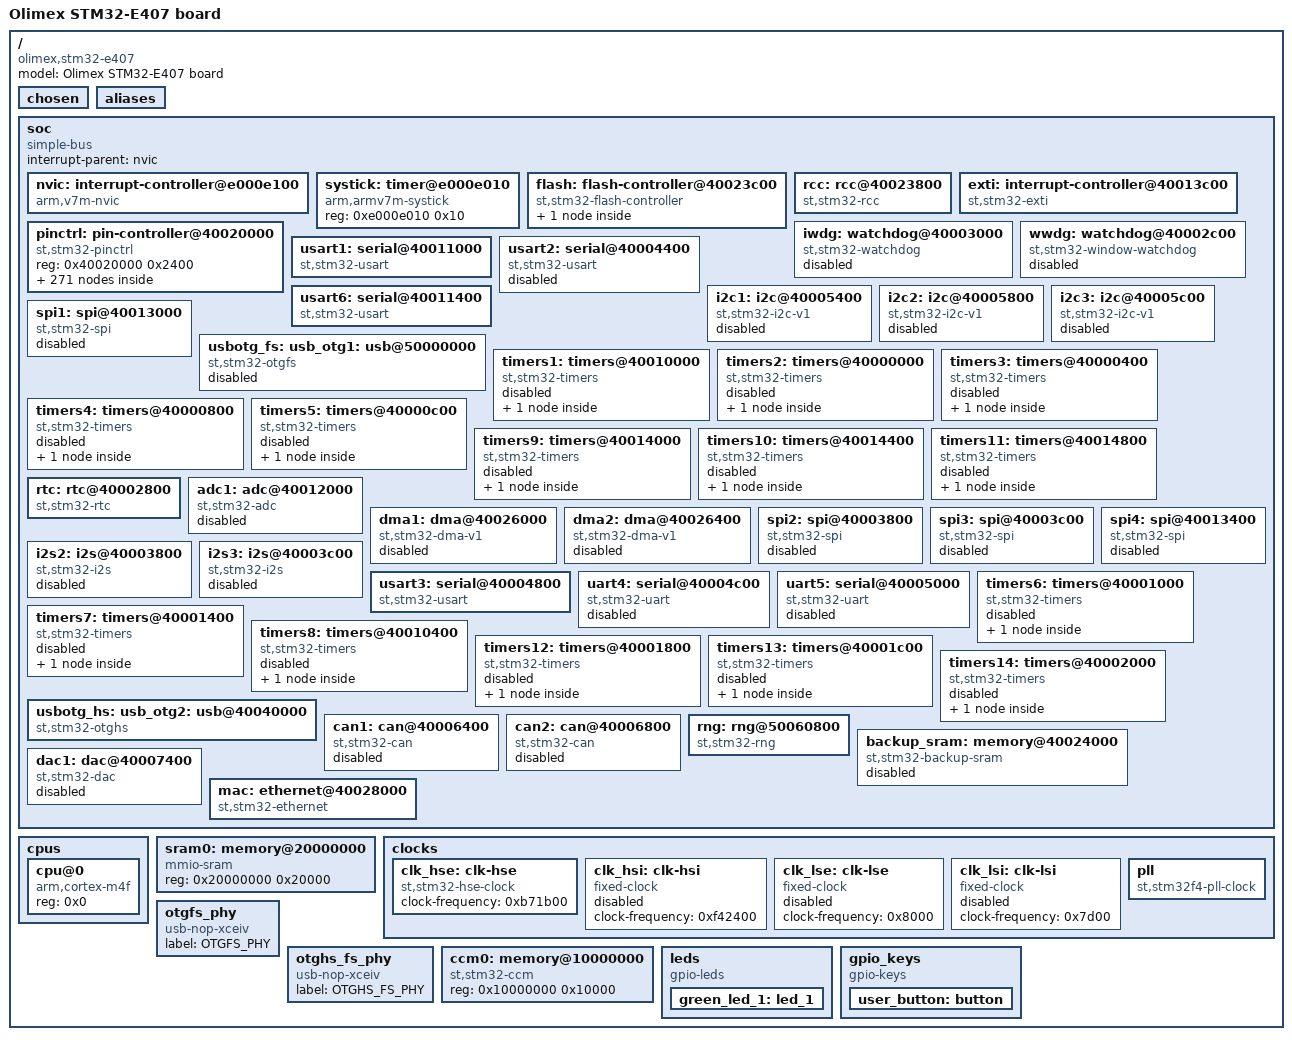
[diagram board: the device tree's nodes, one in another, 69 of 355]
/dts-v1/;

/ {
	#address-cells = < 0x1 >;
	#size-cells = < 0x1 >;
	model = "Olimex STM32-E407 board";
	compatible = "olimex,stm32-e407";
	chosen {
		zephyr,flash-controller = &flash;
		zephyr,entropy = &rng;
		zephyr,console = &usart1;
		zephyr,shell-uart = &usart1;
		zephyr,sram = &sram0;
		zephyr,flash = &flash0;
		zephyr,ccm = &ccm0;
	};
	aliases {
		led0 = &green_led_1;
		sw0 = &user_button;
	};
	soc {
		#address-cells = < 0x1 >;
		#size-cells = < 0x1 >;
		compatible = "simple-bus";
		interrupt-parent = < &nvic >;
		ranges;
		nvic: interrupt-controller@e000e100 {
			compatible = "arm,v7m-nvic";
			reg = < 0xe000e100 0xc00 >;
			interrupt-controller;
			#interrupt-cells = < 0x2 >;
			arm,num-irq-priority-bits = < 0x4 >;
			phandle = < 0x1 >;
		};
		systick: timer@e000e010 {
			compatible = "arm,armv7m-systick";
			reg = < 0xe000e010 0x10 >;
		};
		flash: flash-controller@40023c00 {
			compatible = "st,stm32-flash-controller", "st,stm32f4-flash-controller";
			label = "FLASH_CTRL";
			reg = < 0x40023c00 0x400 >;
			interrupts = < 0x4 0x0 >;
			#address-cells = < 0x1 >;
			#size-cells = < 0x1 >;
			flash0: flash@8000000 {
				compatible = "soc-nv-flash";
				label = "FLASH_STM32";
				write-block-size = < 0x1 >;
				reg = < 0x8000000 0x100000 >;
			};
		};
		rcc: rcc@40023800 {
			compatible = "st,stm32-rcc";
			#clock-cells = < 0x2 >;
			reg = < 0x40023800 0x400 >;
			clocks = < &pll >;
			clock-frequency = < 0xa037a00 >;
			ahb-prescaler = < 0x1 >;
			apb1-prescaler = < 0x4 >;
			apb2-prescaler = < 0x2 >;
			phandle = < 0x3 >;
		};
		exti: interrupt-controller@40013c00 {
			compatible = "st,stm32-exti";
			interrupt-controller;
			#interrupt-cells = < 0x1 >;
			reg = < 0x40013c00 0x400 >;
		};
		pinctrl: pin-controller@40020000 {
			compatible = "st,stm32-pinctrl";
			#address-cells = < 0x1 >;
			#size-cells = < 0x1 >;
			reg = < 0x40020000 0x2400 >;
			gpioa: gpio@40020000 {
				compatible = "st,stm32-gpio";
				gpio-controller;
				#gpio-cells = < 0x2 >;
				reg = < 0x40020000 0x400 >;
				clocks = < &rcc 0x0 0x1 >;
				label = "GPIOA";
				phandle = < 0x1e >;
			};
			gpiob: gpio@40020400 {
				compatible = "st,stm32-gpio";
				gpio-controller;
				#gpio-cells = < 0x2 >;
				reg = < 0x40020400 0x400 >;
				clocks = < &rcc 0x0 0x2 >;
				label = "GPIOB";
				phandle = < 0x8 >;
			};
			gpioc: gpio@40020800 {
				compatible = "st,stm32-gpio";
				gpio-controller;
				#gpio-cells = < 0x2 >;
				reg = < 0x40020800 0x400 >;
				clocks = < &rcc 0x0 0x4 >;
				label = "GPIOC";
				phandle = < 0x1d >;
			};
			gpiod: gpio@40020c00 {
				compatible = "st,stm32-gpio";
				gpio-controller;
				#gpio-cells = < 0x2 >;
				reg = < 0x40020c00 0x400 >;
				clocks = < &rcc 0x0 0x8 >;
				label = "GPIOD";
			};
			gpioe: gpio@40021000 {
				compatible = "st,stm32-gpio";
				gpio-controller;
				#gpio-cells = < 0x2 >;
				reg = < 0x40021000 0x400 >;
				clocks = < &rcc 0x0 0x10 >;
				label = "GPIOE";
			};
			gpioh: gpio@40021c00 {
				compatible = "st,stm32-gpio";
				gpio-controller;
				#gpio-cells = < 0x2 >;
				reg = < 0x40021c00 0x400 >;
				clocks = < &rcc 0x0 0x80 >;
				label = "GPIOH";
			};
			gpiof: gpio@40021400 {
				compatible = "st,stm32-gpio";
				gpio-controller;
				#gpio-cells = < 0x2 >;
				reg = < 0x40021400 0x400 >;
				clocks = < &rcc 0x0 0x20 >;
				label = "GPIOF";
			};
			gpiog: gpio@40021800 {
				compatible = "st,stm32-gpio";
				gpio-controller;
				#gpio-cells = < 0x2 >;
				reg = < 0x40021800 0x400 >;
				clocks = < &rcc 0x0 0x40 >;
				label = "GPIOG";
			};
			gpioi: gpio@40022000 {
				compatible = "st,stm32-gpio";
				gpio-controller;
				#gpio-cells = < 0x2 >;
				reg = < 0x40022000 0x400 >;
				clocks = < &rcc 0x0 0x100 >;
				label = "GPIOI";
			};
			adc1_in0_pa0: adc1_in0_pa0 {
				pinmux = < 0x10 >;
			};
			adc1_in1_pa1: adc1_in1_pa1 {
				pinmux = < 0x110 >;
			};
			adc1_in2_pa2: adc1_in2_pa2 {
				pinmux = < 0x210 >;
			};
			adc1_in3_pa3: adc1_in3_pa3 {
				pinmux = < 0x310 >;
			};
			adc1_in4_pa4: adc1_in4_pa4 {
				pinmux = < 0x410 >;
			};
			adc1_in5_pa5: adc1_in5_pa5 {
				pinmux = < 0x510 >;
			};
			adc1_in6_pa6: adc1_in6_pa6 {
				pinmux = < 0x610 >;
			};
			adc1_in7_pa7: adc1_in7_pa7 {
				pinmux = < 0x710 >;
			};
			adc1_in8_pb0: adc1_in8_pb0 {
				pinmux = < 0x1010 >;
			};
			adc1_in9_pb1: adc1_in9_pb1 {
				pinmux = < 0x1110 >;
			};
			adc1_in10_pc0: adc1_in10_pc0 {
				pinmux = < 0x2010 >;
			};
			adc1_in11_pc1: adc1_in11_pc1 {
				pinmux = < 0x2110 >;
			};
			adc1_in12_pc2: adc1_in12_pc2 {
				pinmux = < 0x2210 >;
			};
			adc1_in13_pc3: adc1_in13_pc3 {
				pinmux = < 0x2310 >;
			};
			adc1_in14_pc4: adc1_in14_pc4 {
				pinmux = < 0x2410 >;
			};
			adc1_in15_pc5: adc1_in15_pc5 {
				pinmux = < 0x2510 >;
			};
			adc2_in0_pa0: adc2_in0_pa0 {
				pinmux = < 0x10 >;
			};
			adc2_in1_pa1: adc2_in1_pa1 {
				pinmux = < 0x110 >;
			};
			adc2_in2_pa2: adc2_in2_pa2 {
				pinmux = < 0x210 >;
			};
			adc2_in3_pa3: adc2_in3_pa3 {
				pinmux = < 0x310 >;
			};
			adc2_in4_pa4: adc2_in4_pa4 {
				pinmux = < 0x410 >;
			};
			adc2_in5_pa5: adc2_in5_pa5 {
				pinmux = < 0x510 >;
			};
			adc2_in6_pa6: adc2_in6_pa6 {
				pinmux = < 0x610 >;
			};
			adc2_in7_pa7: adc2_in7_pa7 {
				pinmux = < 0x710 >;
			};
			adc2_in8_pb0: adc2_in8_pb0 {
				pinmux = < 0x1010 >;
			};
			adc2_in9_pb1: adc2_in9_pb1 {
				pinmux = < 0x1110 >;
			};
			adc2_in10_pc0: adc2_in10_pc0 {
				pinmux = < 0x2010 >;
			};
			adc2_in11_pc1: adc2_in11_pc1 {
				pinmux = < 0x2110 >;
			};
			adc2_in12_pc2: adc2_in12_pc2 {
				pinmux = < 0x2210 >;
			};
			adc2_in13_pc3: adc2_in13_pc3 {
				pinmux = < 0x2310 >;
			};
			adc2_in14_pc4: adc2_in14_pc4 {
				pinmux = < 0x2410 >;
			};
			adc2_in15_pc5: adc2_in15_pc5 {
				pinmux = < 0x2510 >;
			};
			adc3_in0_pa0: adc3_in0_pa0 {
				pinmux = < 0x10 >;
			};
			adc3_in1_pa1: adc3_in1_pa1 {
				pinmux = < 0x110 >;
			};
			adc3_in2_pa2: adc3_in2_pa2 {
				pinmux = < 0x210 >;
			};
			adc3_in3_pa3: adc3_in3_pa3 {
				pinmux = < 0x310 >;
			};
			adc3_in10_pc0: adc3_in10_pc0 {
				pinmux = < 0x2010 >;
			};
			adc3_in11_pc1: adc3_in11_pc1 {
				pinmux = < 0x2110 >;
			};
			adc3_in12_pc2: adc3_in12_pc2 {
				pinmux = < 0x2210 >;
			};
			adc3_in13_pc3: adc3_in13_pc3 {
				pinmux = < 0x2310 >;
			};
			adc3_in9_pf3: adc3_in9_pf3 {
				pinmux = < 0x5310 >;
			};
			adc3_in14_pf4: adc3_in14_pf4 {
				pinmux = < 0x5410 >;
			};
			adc3_in15_pf5: adc3_in15_pf5 {
				pinmux = < 0x5510 >;
			};
			adc3_in4_pf6: adc3_in4_pf6 {
				pinmux = < 0x5610 >;
			};
			adc3_in5_pf7: adc3_in5_pf7 {
				pinmux = < 0x5710 >;
			};
			adc3_in6_pf8: adc3_in6_pf8 {
				pinmux = < 0x5810 >;
			};
			adc3_in7_pf9: adc3_in7_pf9 {
				pinmux = < 0x5910 >;
			};
			adc3_in8_pf10: adc3_in8_pf10 {
				pinmux = < 0x5a10 >;
			};
			can1_rx_pa11: can1_rx_pa11 {
				pinmux = < 0xb09 >;
				bias-pull-up;
			};
			can1_rx_pb8: can1_rx_pb8 {
				pinmux = < 0x1809 >;
				bias-pull-up;
			};
			can1_rx_pd0: can1_rx_pd0 {
				pinmux = < 0x3009 >;
				bias-pull-up;
			};
			can2_rx_pb5: can2_rx_pb5 {
				pinmux = < 0x1509 >;
				bias-pull-up;
			};
			can2_rx_pb12: can2_rx_pb12 {
				pinmux = < 0x1c09 >;
				bias-pull-up;
			};
			can1_tx_pa12: can1_tx_pa12 {
				pinmux = < 0xc09 >;
			};
			can1_tx_pb9: can1_tx_pb9 {
				pinmux = < 0x1909 >;
			};
			can1_tx_pd1: can1_tx_pd1 {
				pinmux = < 0x3109 >;
			};
			can2_tx_pb6: can2_tx_pb6 {
				pinmux = < 0x1609 >;
			};
			can2_tx_pb13: can2_tx_pb13 {
				pinmux = < 0x1d09 >;
			};
			dac_out1_pa4: dac_out1_pa4 {
				pinmux = < 0x410 >;
			};
			dac_out2_pa5: dac_out2_pa5 {
				pinmux = < 0x510 >;
			};
			eth_col_pa3: eth_col_pa3 {
				pinmux = < 0x30b >;
				slew-rate = "very-high-speed";
				phandle = < 0x17 >;
			};
			eth_crs_pa0: eth_crs_pa0 {
				pinmux = < 0xb >;
				slew-rate = "very-high-speed";
			};
			eth_crs_dv_pa7: eth_crs_dv_pa7 {
				pinmux = < 0x70b >;
				slew-rate = "very-high-speed";
				phandle = < 0x18 >;
			};
			eth_mdc_pc1: eth_mdc_pc1 {
				pinmux = < 0x210b >;
				slew-rate = "very-high-speed";
				phandle = < 0x12 >;
			};
			eth_mdio_pa2: eth_mdio_pa2 {
				pinmux = < 0x20b >;
				slew-rate = "very-high-speed";
				phandle = < 0x16 >;
			};
			eth_pps_out_pb5: eth_pps_out_pb5 {
				pinmux = < 0x150b >;
				slew-rate = "very-high-speed";
			};
			eth_pps_out_pg8: eth_pps_out_pg8 {
				pinmux = < 0x680b >;
				slew-rate = "very-high-speed";
			};
			eth_ref_clk_pa1: eth_ref_clk_pa1 {
				pinmux = < 0x10b >;
				slew-rate = "very-high-speed";
				phandle = < 0x15 >;
			};
			eth_rxd0_pc4: eth_rxd0_pc4 {
				pinmux = < 0x240b >;
				slew-rate = "very-high-speed";
				phandle = < 0x13 >;
			};
			eth_rxd1_pc5: eth_rxd1_pc5 {
				pinmux = < 0x250b >;
				slew-rate = "very-high-speed";
				phandle = < 0x14 >;
			};
			eth_rxd2_pb0: eth_rxd2_pb0 {
				pinmux = < 0x100b >;
				slew-rate = "very-high-speed";
			};
			eth_rxd3_pb1: eth_rxd3_pb1 {
				pinmux = < 0x110b >;
				slew-rate = "very-high-speed";
			};
			eth_rx_clk_pa1: eth_rx_clk_pa1 {
				pinmux = < 0x10b >;
				slew-rate = "very-high-speed";
			};
			eth_rx_dv_pa7: eth_rx_dv_pa7 {
				pinmux = < 0x70b >;
				slew-rate = "very-high-speed";
			};
			eth_rx_er_pb10: eth_rx_er_pb10 {
				pinmux = < 0x1a0b >;
				slew-rate = "very-high-speed";
			};
			eth_txd0_pb12: eth_txd0_pb12 {
				pinmux = < 0x1c0b >;
				slew-rate = "very-high-speed";
			};
			eth_txd0_pg13: eth_txd0_pg13 {
				pinmux = < 0x6d0b >;
				slew-rate = "very-high-speed";
				phandle = < 0x1a >;
			};
			eth_txd1_pb13: eth_txd1_pb13 {
				pinmux = < 0x1d0b >;
				slew-rate = "very-high-speed";
			};
			eth_txd1_pg14: eth_txd1_pg14 {
				pinmux = < 0x6e0b >;
				slew-rate = "very-high-speed";
				phandle = < 0x1b >;
			};
			eth_txd2_pc2: eth_txd2_pc2 {
				pinmux = < 0x220b >;
				slew-rate = "very-high-speed";
			};
			eth_txd3_pb8: eth_txd3_pb8 {
				pinmux = < 0x180b >;
				slew-rate = "very-high-speed";
			};
			eth_txd3_pe2: eth_txd3_pe2 {
				pinmux = < 0x420b >;
				slew-rate = "very-high-speed";
			};
			eth_tx_clk_pc3: eth_tx_clk_pc3 {
				pinmux = < 0x230b >;
				slew-rate = "very-high-speed";
			};
			eth_tx_en_pb11: eth_tx_en_pb11 {
				pinmux = < 0x1b0b >;
				slew-rate = "very-high-speed";
			};
			eth_tx_en_pg11: eth_tx_en_pg11 {
				pinmux = < 0x6b0b >;
				slew-rate = "very-high-speed";
				phandle = < 0x19 >;
			};
			i2c1_scl_pb6: i2c1_scl_pb6 {
				pinmux = < 0x1604 >;
				bias-pull-up;
				drive-open-drain;
			};
			i2c1_scl_pb8: i2c1_scl_pb8 {
				pinmux = < 0x1804 >;
				bias-pull-up;
				drive-open-drain;
			};
			i2c2_scl_pb10: i2c2_scl_pb10 {
				pinmux = < 0x1a04 >;
				bias-pull-up;
				drive-open-drain;
			};
			i2c2_scl_pf1: i2c2_scl_pf1 {
				pinmux = < 0x5104 >;
				bias-pull-up;
				drive-open-drain;
			};
			i2c3_scl_pa8: i2c3_scl_pa8 {
				pinmux = < 0x804 >;
				bias-pull-up;
				drive-open-drain;
			};
			i2c1_sda_pb7: i2c1_sda_pb7 {
				pinmux = < 0x1704 >;
				bias-pull-up;
				drive-open-drain;
			};
			i2c1_sda_pb9: i2c1_sda_pb9 {
				pinmux = < 0x1904 >;
				bias-pull-up;
				drive-open-drain;
			};
			i2c2_sda_pb11: i2c2_sda_pb11 {
				pinmux = < 0x1b04 >;
				bias-pull-up;
				drive-open-drain;
			};
			i2c2_sda_pf0: i2c2_sda_pf0 {
				pinmux = < 0x5004 >;
				bias-pull-up;
				drive-open-drain;
			};
			i2c3_sda_pc9: i2c3_sda_pc9 {
				pinmux = < 0x2904 >;
				bias-pull-up;
				drive-open-drain;
			};
			i2s2_ck_pb10: i2s2_ck_pb10 {
				pinmux = < 0x1a05 >;
				slew-rate = "very-high-speed";
			};
			i2s2_ck_pb13: i2s2_ck_pb13 {
				pinmux = < 0x1d05 >;
				slew-rate = "very-high-speed";
			};
			i2s3_ck_pb3: i2s3_ck_pb3 {
				pinmux = < 0x1306 >;
				slew-rate = "very-high-speed";
			};
			i2s3_ck_pc10: i2s3_ck_pc10 {
				pinmux = < 0x2a06 >;
				slew-rate = "very-high-speed";
			};
			i2s2_sd_pb15: i2s2_sd_pb15 {
				pinmux = < 0x1f05 >;
			};
			i2s2_sd_pc3: i2s2_sd_pc3 {
				pinmux = < 0x2305 >;
			};
			i2s3_sd_pb5: i2s3_sd_pb5 {
				pinmux = < 0x1506 >;
			};
			i2s3_sd_pc12: i2s3_sd_pc12 {
				pinmux = < 0x2c06 >;
			};
			i2s2_ws_pb9: i2s2_ws_pb9 {
				pinmux = < 0x1905 >;
			};
			i2s2_ws_pb12: i2s2_ws_pb12 {
				pinmux = < 0x1c05 >;
			};
			i2s3_ws_pa4: i2s3_ws_pa4 {
				pinmux = < 0x406 >;
			};
			i2s3_ws_pa15: i2s3_ws_pa15 {
				pinmux = < 0xf06 >;
			};
			spi1_miso_pa6: spi1_miso_pa6 {
				pinmux = < 0x605 >;
				bias-pull-down;
			};
			spi1_miso_pb4: spi1_miso_pb4 {
				pinmux = < 0x1405 >;
				bias-pull-down;
			};
			spi2_miso_pb14: spi2_miso_pb14 {
				pinmux = < 0x1e05 >;
				bias-pull-down;
			};
			spi2_miso_pc2: spi2_miso_pc2 {
				pinmux = < 0x2205 >;
				bias-pull-down;
			};
			spi3_miso_pb4: spi3_miso_pb4 {
				pinmux = < 0x1406 >;
				bias-pull-down;
			};
			spi3_miso_pc11: spi3_miso_pc11 {
				pinmux = < 0x2b06 >;
				bias-pull-down;
			};
			spi1_mosi_pa7: spi1_mosi_pa7 {
				pinmux = < 0x705 >;
				bias-pull-down;
			};
			spi1_mosi_pb5: spi1_mosi_pb5 {
				pinmux = < 0x1505 >;
				bias-pull-down;
			};
			spi2_mosi_pb15: spi2_mosi_pb15 {
				pinmux = < 0x1f05 >;
				bias-pull-down;
			};
			spi2_mosi_pc3: spi2_mosi_pc3 {
				pinmux = < 0x2305 >;
				bias-pull-down;
			};
			spi3_mosi_pb5: spi3_mosi_pb5 {
				pinmux = < 0x1506 >;
				bias-pull-down;
			};
			spi3_mosi_pc12: spi3_mosi_pc12 {
				pinmux = < 0x2c06 >;
				bias-pull-down;
			};
			spi1_nss_pa4: spi1_nss_pa4 {
				pinmux = < 0x405 >;
				bias-pull-up;
			};
			spi1_nss_pa15: spi1_nss_pa15 {
				pinmux = < 0xf05 >;
				bias-pull-up;
			};
			spi2_nss_pb9: spi2_nss_pb9 {
				pinmux = < 0x1905 >;
				bias-pull-up;
			};
			spi2_nss_pb12: spi2_nss_pb12 {
				pinmux = < 0x1c05 >;
				bias-pull-up;
			};
			spi3_nss_pa4: spi3_nss_pa4 {
				pinmux = < 0x406 >;
				bias-pull-up;
			};
			spi3_nss_pa15: spi3_nss_pa15 {
				pinmux = < 0xf06 >;
				bias-pull-up;
			};
			spi1_sck_pa5: spi1_sck_pa5 {
				pinmux = < 0x505 >;
				bias-pull-down;
				slew-rate = "very-high-speed";
			};
			spi1_sck_pb3: spi1_sck_pb3 {
				pinmux = < 0x1305 >;
				bias-pull-down;
				slew-rate = "very-high-speed";
			};
			spi2_sck_pb10: spi2_sck_pb10 {
				pinmux = < 0x1a05 >;
				bias-pull-down;
				slew-rate = "very-high-speed";
			};
			spi2_sck_pb13: spi2_sck_pb13 {
				pinmux = < 0x1d05 >;
				bias-pull-down;
				slew-rate = "very-high-speed";
			};
			spi3_sck_pb3: spi3_sck_pb3 {
				pinmux = < 0x1306 >;
				bias-pull-down;
				slew-rate = "very-high-speed";
			};
			spi3_sck_pc10: spi3_sck_pc10 {
				pinmux = < 0x2a06 >;
				bias-pull-down;
				slew-rate = "very-high-speed";
			};
			tim10_ch1_pb8: tim10_ch1_pb8 {
				pinmux = < 0x1803 >;
			};
			tim10_ch1_pf6: tim10_ch1_pf6 {
				pinmux = < 0x5603 >;
			};
			tim1_ch1n_pa7: tim1_ch1n_pa7 {
				pinmux = < 0x701 >;
			};
			tim1_ch1_pa8: tim1_ch1_pa8 {
				pinmux = < 0x801 >;
			};
			tim1_ch2_pa9: tim1_ch2_pa9 {
				pinmux = < 0x901 >;
			};
			tim1_ch3_pa10: tim1_ch3_pa10 {
				pinmux = < 0xa01 >;
			};
			tim1_ch4_pa11: tim1_ch4_pa11 {
				pinmux = < 0xb01 >;
			};
			tim1_ch2n_pb0: tim1_ch2n_pb0 {
				pinmux = < 0x1001 >;
			};
			tim1_ch3n_pb1: tim1_ch3n_pb1 {
				pinmux = < 0x1101 >;
			};
			tim11_ch1_pb9: tim11_ch1_pb9 {
				pinmux = < 0x1903 >;
			};
			tim1_ch1n_pb13: tim1_ch1n_pb13 {
				pinmux = < 0x1d01 >;
			};
			tim1_ch2n_pb14: tim1_ch2n_pb14 {
				pinmux = < 0x1e01 >;
			};
			tim1_ch3n_pb15: tim1_ch3n_pb15 {
				pinmux = < 0x1f01 >;
			};
			tim1_ch1n_pe8: tim1_ch1n_pe8 {
				pinmux = < 0x4801 >;
			};
			tim1_ch1_pe9: tim1_ch1_pe9 {
				pinmux = < 0x4901 >;
			};
			tim1_ch2n_pe10: tim1_ch2n_pe10 {
				pinmux = < 0x4a01 >;
			};
			tim1_ch2_pe11: tim1_ch2_pe11 {
				pinmux = < 0x4b01 >;
			};
			tim1_ch3n_pe12: tim1_ch3n_pe12 {
				pinmux = < 0x4c01 >;
			};
			tim1_ch3_pe13: tim1_ch3_pe13 {
				pinmux = < 0x4d01 >;
			};
			tim1_ch4_pe14: tim1_ch4_pe14 {
				pinmux = < 0x4e01 >;
			};
			tim11_ch1_pf7: tim11_ch1_pf7 {
				pinmux = < 0x5703 >;
			};
			tim2_ch1_pa0: tim2_ch1_pa0 {
				pinmux = < 0x1 >;
			};
			tim2_ch2_pa1: tim2_ch2_pa1 {
				pinmux = < 0x101 >;
			};
			tim2_ch3_pa2: tim2_ch3_pa2 {
				pinmux = < 0x201 >;
			};
			tim2_ch4_pa3: tim2_ch4_pa3 {
				pinmux = < 0x301 >;
			};
			tim2_ch1_pa5: tim2_ch1_pa5 {
				pinmux = < 0x501 >;
			};
			tim2_ch1_pa15: tim2_ch1_pa15 {
				pinmux = < 0xf01 >;
			};
			tim2_ch2_pb3: tim2_ch2_pb3 {
				pinmux = < 0x1301 >;
			};
			tim2_ch3_pb10: tim2_ch3_pb10 {
				pinmux = < 0x1a01 >;
			};
			tim2_ch4_pb11: tim2_ch4_pb11 {
				pinmux = < 0x1b01 >;
			};
			tim12_ch1_pb14: tim12_ch1_pb14 {
				pinmux = < 0x1e09 >;
			};
			tim12_ch2_pb15: tim12_ch2_pb15 {
				pinmux = < 0x1f09 >;
			};
			tim13_ch1_pa6: tim13_ch1_pa6 {
				pinmux = < 0x609 >;
			};
			tim3_ch1_pa6: tim3_ch1_pa6 {
				pinmux = < 0x602 >;
			};
			tim3_ch2_pa7: tim3_ch2_pa7 {
				pinmux = < 0x702 >;
			};
			tim3_ch3_pb0: tim3_ch3_pb0 {
				pinmux = < 0x1002 >;
			};
			tim3_ch4_pb1: tim3_ch4_pb1 {
				pinmux = < 0x1102 >;
			};
			tim3_ch1_pb4: tim3_ch1_pb4 {
				pinmux = < 0x1402 >;
			};
			tim3_ch2_pb5: tim3_ch2_pb5 {
				pinmux = < 0x1502 >;
			};
			tim3_ch1_pc6: tim3_ch1_pc6 {
				pinmux = < 0x2602 >;
			};
			tim3_ch2_pc7: tim3_ch2_pc7 {
				pinmux = < 0x2702 >;
			};
			tim3_ch3_pc8: tim3_ch3_pc8 {
				pinmux = < 0x2802 >;
			};
			tim3_ch4_pc9: tim3_ch4_pc9 {
				pinmux = < 0x2902 >;
			};
			tim13_ch1_pf8: tim13_ch1_pf8 {
				pinmux = < 0x5809 >;
			};
			tim14_ch1_pa7: tim14_ch1_pa7 {
				pinmux = < 0x709 >;
			};
			tim4_ch1_pb6: tim4_ch1_pb6 {
				pinmux = < 0x1602 >;
			};
			tim4_ch2_pb7: tim4_ch2_pb7 {
				pinmux = < 0x1702 >;
			};
			tim4_ch3_pb8: tim4_ch3_pb8 {
				pinmux = < 0x1802 >;
			};
			tim4_ch4_pb9: tim4_ch4_pb9 {
				pinmux = < 0x1902 >;
			};
			tim4_ch1_pd12: tim4_ch1_pd12 {
				pinmux = < 0x3c02 >;
			};
			tim4_ch2_pd13: tim4_ch2_pd13 {
				pinmux = < 0x3d02 >;
			};
			tim4_ch3_pd14: tim4_ch3_pd14 {
				pinmux = < 0x3e02 >;
			};
			tim4_ch4_pd15: tim4_ch4_pd15 {
				pinmux = < 0x3f02 >;
			};
			tim14_ch1_pf9: tim14_ch1_pf9 {
				pinmux = < 0x5909 >;
			};
			tim5_ch1_pa0: tim5_ch1_pa0 {
				pinmux = < 0x2 >;
			};
			tim5_ch2_pa1: tim5_ch2_pa1 {
				pinmux = < 0x102 >;
			};
			tim5_ch3_pa2: tim5_ch3_pa2 {
				pinmux = < 0x202 >;
			};
			tim5_ch4_pa3: tim5_ch4_pa3 {
				pinmux = < 0x302 >;
			};
			tim8_ch1n_pa5: tim8_ch1n_pa5 {
				pinmux = < 0x503 >;
			};
			tim8_ch1n_pa7: tim8_ch1n_pa7 {
				pinmux = < 0x703 >;
			};
			tim8_ch2n_pb0: tim8_ch2n_pb0 {
				pinmux = < 0x1003 >;
			};
			tim8_ch3n_pb1: tim8_ch3n_pb1 {
				pinmux = < 0x1103 >;
			};
			tim8_ch2n_pb14: tim8_ch2n_pb14 {
				pinmux = < 0x1e03 >;
			};
			tim8_ch3n_pb15: tim8_ch3n_pb15 {
				pinmux = < 0x1f03 >;
			};
			tim8_ch1_pc6: tim8_ch1_pc6 {
				pinmux = < 0x2603 >;
			};
			tim8_ch2_pc7: tim8_ch2_pc7 {
				pinmux = < 0x2703 >;
			};
			tim8_ch3_pc8: tim8_ch3_pc8 {
				pinmux = < 0x2803 >;
			};
			tim8_ch4_pc9: tim8_ch4_pc9 {
				pinmux = < 0x2903 >;
			};
			tim9_ch1_pa2: tim9_ch1_pa2 {
				pinmux = < 0x203 >;
			};
			tim9_ch2_pa3: tim9_ch2_pa3 {
				pinmux = < 0x303 >;
			};
			tim9_ch1_pe5: tim9_ch1_pe5 {
				pinmux = < 0x4503 >;
			};
			tim9_ch2_pe6: tim9_ch2_pe6 {
				pinmux = < 0x4603 >;
			};
			usart1_cts_pa11: usart1_cts_pa11 {
				pinmux = < 0xb07 >;
				bias-pull-up;
				drive-open-drain;
			};
			usart2_cts_pa0: usart2_cts_pa0 {
				pinmux = < 0x7 >;
				bias-pull-up;
				drive-open-drain;
			};
			usart2_cts_pd3: usart2_cts_pd3 {
				pinmux = < 0x3307 >;
				bias-pull-up;
				drive-open-drain;
			};
			usart3_cts_pb13: usart3_cts_pb13 {
				pinmux = < 0x1d07 >;
				bias-pull-up;
				drive-open-drain;
			};
			usart3_cts_pd11: usart3_cts_pd11 {
				pinmux = < 0x3b07 >;
				bias-pull-up;
				drive-open-drain;
			};
			usart6_cts_pg13: usart6_cts_pg13 {
				pinmux = < 0x6d08 >;
				bias-pull-up;
				drive-open-drain;
			};
			usart6_cts_pg15: usart6_cts_pg15 {
				pinmux = < 0x6f08 >;
				bias-pull-up;
				drive-open-drain;
			};
			usart1_rts_pa12: usart1_rts_pa12 {
				pinmux = < 0xc07 >;
				bias-pull-up;
				drive-open-drain;
			};
			usart2_rts_pa1: usart2_rts_pa1 {
				pinmux = < 0x107 >;
				bias-pull-up;
				drive-open-drain;
			};
			usart2_rts_pd4: usart2_rts_pd4 {
				pinmux = < 0x3407 >;
				bias-pull-up;
				drive-open-drain;
			};
			usart3_rts_pb14: usart3_rts_pb14 {
				pinmux = < 0x1e07 >;
				bias-pull-up;
				drive-open-drain;
			};
			usart3_rts_pd12: usart3_rts_pd12 {
				pinmux = < 0x3c07 >;
				bias-pull-up;
				drive-open-drain;
			};
			usart6_rts_pg8: usart6_rts_pg8 {
				pinmux = < 0x6808 >;
				bias-pull-up;
				drive-open-drain;
			};
			usart6_rts_pg12: usart6_rts_pg12 {
				pinmux = < 0x6c08 >;
				bias-pull-up;
				drive-open-drain;
			};
			usart1_rx_pa10: usart1_rx_pa10 {
				pinmux = < 0xa07 >;
			};
			usart1_rx_pb7: usart1_rx_pb7 {
				pinmux = < 0x1707 >;
				phandle = < 0x5 >;
			};
			usart2_rx_pa3: usart2_rx_pa3 {
				pinmux = < 0x307 >;
			};
			usart2_rx_pd6: usart2_rx_pd6 {
				pinmux = < 0x3607 >;
			};
			usart3_rx_pb11: usart3_rx_pb11 {
				pinmux = < 0x1b07 >;
				phandle = < 0xe >;
			};
			usart3_rx_pc11: usart3_rx_pc11 {
				pinmux = < 0x2b07 >;
			};
			usart3_rx_pd9: usart3_rx_pd9 {
				pinmux = < 0x3907 >;
			};
			uart4_rx_pa1: uart4_rx_pa1 {
				pinmux = < 0x108 >;
			};
			uart4_rx_pc11: uart4_rx_pc11 {
				pinmux = < 0x2b08 >;
			};
			uart5_rx_pd2: uart5_rx_pd2 {
				pinmux = < 0x3208 >;
			};
			usart6_rx_pc7: usart6_rx_pc7 {
				pinmux = < 0x2708 >;
				phandle = < 0x7 >;
			};
			usart6_rx_pg9: usart6_rx_pg9 {
				pinmux = < 0x6908 >;
			};
			usart1_tx_pa9: usart1_tx_pa9 {
				pinmux = < 0x907 >;
				bias-pull-up;
			};
			usart1_tx_pb6: usart1_tx_pb6 {
				pinmux = < 0x1607 >;
				bias-pull-up;
				phandle = < 0x4 >;
			};
			usart2_tx_pa2: usart2_tx_pa2 {
				pinmux = < 0x207 >;
				bias-pull-up;
			};
			usart2_tx_pd5: usart2_tx_pd5 {
				pinmux = < 0x3507 >;
				bias-pull-up;
			};
			usart3_tx_pb10: usart3_tx_pb10 {
				pinmux = < 0x1a07 >;
				bias-pull-up;
				phandle = < 0xd >;
			};
			usart3_tx_pc10: usart3_tx_pc10 {
				pinmux = < 0x2a07 >;
				bias-pull-up;
			};
			usart3_tx_pd8: usart3_tx_pd8 {
				pinmux = < 0x3807 >;
				bias-pull-up;
			};
			uart4_tx_pa0: uart4_tx_pa0 {
				pinmux = < 0x8 >;
				bias-pull-up;
			};
			uart4_tx_pc10: uart4_tx_pc10 {
				pinmux = < 0x2a08 >;
				bias-pull-up;
			};
			uart5_tx_pc12: uart5_tx_pc12 {
				pinmux = < 0x2c08 >;
				bias-pull-up;
			};
			usart6_tx_pc6: usart6_tx_pc6 {
				pinmux = < 0x2608 >;
				bias-pull-up;
				phandle = < 0x6 >;
			};
			usart6_tx_pg14: usart6_tx_pg14 {
				pinmux = < 0x6e08 >;
				bias-pull-up;
			};
			usb_otg_fs_sof_pa8: usb_otg_fs_sof_pa8 {
				pinmux = < 0x80a >;
			};
			usb_otg_fs_vbus_pa9: usb_otg_fs_vbus_pa9 {
				pinmux = < 0x910 >;
			};
			usb_otg_fs_id_pa10: usb_otg_fs_id_pa10 {
				pinmux = < 0xa0a >;
			};
			usb_otg_fs_dm_pa11: usb_otg_fs_dm_pa11 {
				pinmux = < 0xb0a >;
				phandle = < 0xa >;
			};
			usb_otg_fs_dp_pa12: usb_otg_fs_dp_pa12 {
				pinmux = < 0xc0a >;
				phandle = < 0xb >;
			};
			usb_otg_hs_sof_pa4: usb_otg_hs_sof_pa4 {
				pinmux = < 0x40c >;
			};
			usb_otg_hs_id_pb12: usb_otg_hs_id_pb12 {
				pinmux = < 0x1c0c >;
			};
			usb_otg_hs_vbus_pb13: usb_otg_hs_vbus_pb13 {
				pinmux = < 0x1d10 >;
			};
			usb_otg_hs_dm_pb14: usb_otg_hs_dm_pb14 {
				pinmux = < 0x1e0c >;
				phandle = < 0x10 >;
			};
			usb_otg_hs_dp_pb15: usb_otg_hs_dp_pb15 {
				pinmux = < 0x1f0c >;
				phandle = < 0x11 >;
			};
			usb_otg_hs_ulpi_d0_pa3: usb_otg_hs_ulpi_d0_pa3 {
				pinmux = < 0x30a >;
			};
			usb_otg_hs_ulpi_d1_pb0: usb_otg_hs_ulpi_d1_pb0 {
				pinmux = < 0x100a >;
			};
			usb_otg_hs_ulpi_d2_pb1: usb_otg_hs_ulpi_d2_pb1 {
				pinmux = < 0x110a >;
			};
			usb_otg_hs_ulpi_d7_pb5: usb_otg_hs_ulpi_d7_pb5 {
				pinmux = < 0x150a >;
			};
			usb_otg_hs_ulpi_d3_pb10: usb_otg_hs_ulpi_d3_pb10 {
				pinmux = < 0x1a0a >;
			};
			usb_otg_hs_ulpi_d4_pb11: usb_otg_hs_ulpi_d4_pb11 {
				pinmux = < 0x1b0a >;
			};
			usb_otg_hs_ulpi_d5_pb12: usb_otg_hs_ulpi_d5_pb12 {
				pinmux = < 0x1c0a >;
			};
			usb_otg_hs_ulpi_d6_pb13: usb_otg_hs_ulpi_d6_pb13 {
				pinmux = < 0x1d0a >;
			};
			usb_otg_hs_ulpi_stp_pc0: usb_otg_hs_ulpi_stp_pc0 {
				pinmux = < 0x200a >;
			};
			usb_otg_hs_ulpi_dir_pc2: usb_otg_hs_ulpi_dir_pc2 {
				pinmux = < 0x220a >;
			};
			usb_otg_hs_ulpi_nxt_pc3: usb_otg_hs_ulpi_nxt_pc3 {
				pinmux = < 0x230a >;
			};
		};
		iwdg: watchdog@40003000 {
			compatible = "st,stm32-watchdog";
			reg = < 0x40003000 0x400 >;
			label = "IWDG";
			status = "disabled";
		};
		wwdg: watchdog@40002c00 {
			compatible = "st,stm32-window-watchdog";
			reg = < 0x40002c00 0x400 >;
			clocks = < &rcc 0x2 0x800 >;
			label = "WWDG";
			interrupts = < 0x0 0x7 >;
			status = "disabled";
		};
		usart1: serial@40011000 {
			compatible = "st,stm32-usart", "st,stm32-uart";
			reg = < 0x40011000 0x400 >;
			clocks = < &rcc 0x3 0x10 >;
			interrupts = < 0x25 0x0 >;
			status = "okay";
			label = "UART_1";
			pinctrl-0 = < &usart1_tx_pb6 &usart1_rx_pb7 >;
			current-speed = < 0x1c200 >;
		};
		usart2: serial@40004400 {
			compatible = "st,stm32-usart", "st,stm32-uart";
			reg = < 0x40004400 0x400 >;
			clocks = < &rcc 0x2 0x20000 >;
			interrupts = < 0x26 0x0 >;
			status = "disabled";
			label = "UART_2";
		};
		usart6: serial@40011400 {
			compatible = "st,stm32-usart", "st,stm32-uart";
			reg = < 0x40011400 0x400 >;
			clocks = < &rcc 0x3 0x20 >;
			interrupts = < 0x47 0x0 >;
			status = "okay";
			label = "UART_6";
			pinctrl-0 = < &usart6_tx_pc6 &usart6_rx_pc7 >;
			current-speed = < 0x1c200 >;
		};
		i2c1: i2c@40005400 {
			compatible = "st,stm32-i2c-v1";
			clock-frequency = < 0x186a0 >;
			#address-cells = < 0x1 >;
			#size-cells = < 0x0 >;
			reg = < 0x40005400 0x400 >;
			clocks = < &rcc 0x2 0x200000 >;
			interrupts = < 0x1f 0x0 >, < 0x20 0x0 >;
			interrupt-names = "event", "error";
			status = "disabled";
			label = "I2C_1";
		};
		i2c2: i2c@40005800 {
			compatible = "st,stm32-i2c-v1";
			clock-frequency = < 0x186a0 >;
			#address-cells = < 0x1 >;
			#size-cells = < 0x0 >;
			reg = < 0x40005800 0x400 >;
			clocks = < &rcc 0x2 0x400000 >;
			interrupts = < 0x21 0x0 >, < 0x22 0x0 >;
			interrupt-names = "event", "error";
			status = "disabled";
			label = "I2C_2";
		};
		i2c3: i2c@40005c00 {
			compatible = "st,stm32-i2c-v1";
			clock-frequency = < 0x186a0 >;
			#address-cells = < 0x1 >;
			#size-cells = < 0x0 >;
			reg = < 0x40005c00 0x400 >;
			clocks = < &rcc 0x2 0x800000 >;
			interrupts = < 0x48 0x0 >, < 0x49 0x0 >;
			interrupt-names = "event", "error";
			status = "disabled";
			label = "I2C_3";
		};
		spi1: spi@40013000 {
			compatible = "st,stm32-spi";
			#address-cells = < 0x1 >;
			#size-cells = < 0x0 >;
			reg = < 0x40013000 0x400 >;
			clocks = < &rcc 0x3 0x1000 >;
			interrupts = < 0x23 0x5 >;
			status = "disabled";
			label = "SPI_1";
			cs-gpios = < &gpiob 0x6 0x1 >;
		};
		usbotg_fs: usb_otg1: usb@50000000 {
			compatible = "st,stm32-otgfs";
			reg = < 0x50000000 0x40000 >;
			interrupts = < 0x43 0x0 >;
			interrupt-names = "otgfs";
			num-bidir-endpoints = < 0x4 >;
			ram-size = < 0x500 >;
			maximum-speed = "full-speed";
			phys = < &otgfs_phy >;
			clocks = < &rcc 0x1 0x80 >;
			status = "disabled";
			label = "OTGFS";
			pinctrl-0 = < &usb_otg_fs_dm_pa11 &usb_otg_fs_dp_pa12 >;
		};
		timers1: timers@40010000 {
			compatible = "st,stm32-timers";
			reg = < 0x40010000 0x400 >;
			clocks = < &rcc 0x3 0x1 >;
			interrupts = < 0x18 0x0 >, < 0x19 0x0 >, < 0x1a 0x0 >, < 0x1b 0x0 >;
			interrupt-names = "brk", "up", "trgcom", "cc";
			status = "disabled";
			label = "TIMERS_1";
			pwm {
				compatible = "st,stm32-pwm";
				status = "disabled";
				st,prescaler = < 0x2710 >;
				label = "PWM_1";
				#pwm-cells = < 0x3 >;
			};
		};
		timers2: timers@40000000 {
			compatible = "st,stm32-timers";
			reg = < 0x40000000 0x400 >;
			clocks = < &rcc 0x2 0x1 >;
			interrupts = < 0x1c 0x0 >;
			interrupt-names = "global";
			status = "disabled";
			label = "TIMERS_2";
			pwm {
				compatible = "st,stm32-pwm";
				status = "disabled";
				st,prescaler = < 0x0 >;
				label = "PWM_2";
				#pwm-cells = < 0x3 >;
			};
		};
		timers3: timers@40000400 {
			compatible = "st,stm32-timers";
			reg = < 0x40000400 0x400 >;
			clocks = < &rcc 0x2 0x2 >;
			interrupts = < 0x1d 0x0 >;
			interrupt-names = "global";
			status = "disabled";
			label = "TIMERS_3";
			pwm {
				compatible = "st,stm32-pwm";
				status = "disabled";
				st,prescaler = < 0x2710 >;
				label = "PWM_3";
				#pwm-cells = < 0x3 >;
			};
		};
		timers4: timers@40000800 {
			compatible = "st,stm32-timers";
			reg = < 0x40000800 0x400 >;
			clocks = < &rcc 0x2 0x4 >;
			interrupts = < 0x1e 0x0 >;
			interrupt-names = "global";
			status = "disabled";
			label = "TIMERS_4";
			pwm {
				compatible = "st,stm32-pwm";
				status = "disabled";
				st,prescaler = < 0x2710 >;
				label = "PWM_4";
				#pwm-cells = < 0x3 >;
			};
		};
		timers5: timers@40000c00 {
			compatible = "st,stm32-timers";
			reg = < 0x40000c00 0x400 >;
			clocks = < &rcc 0x2 0x8 >;
			interrupts = < 0x32 0x0 >;
			interrupt-names = "global";
			status = "disabled";
			label = "TIMERS_5";
			pwm {
				compatible = "st,stm32-pwm";
				status = "disabled";
				st,prescaler = < 0x0 >;
				label = "PWM_5";
				#pwm-cells = < 0x3 >;
			};
		};
		timers9: timers@40014000 {
			compatible = "st,stm32-timers";
			reg = < 0x40014000 0x400 >;
			clocks = < &rcc 0x3 0x10000 >;
			interrupts = < 0x18 0x0 >;
			interrupt-names = "global";
			status = "disabled";
			label = "TIMERS_9";
			pwm {
				compatible = "st,stm32-pwm";
				status = "disabled";
				st,prescaler = < 0x2710 >;
				label = "PWM_9";
				#pwm-cells = < 0x3 >;
			};
		};
		timers10: timers@40014400 {
			compatible = "st,stm32-timers";
			reg = < 0x40014400 0x400 >;
			clocks = < &rcc 0x3 0x20000 >;
			interrupts = < 0x19 0x0 >;
			interrupt-names = "global";
			status = "disabled";
			label = "TIMERS_10";
			pwm {
				compatible = "st,stm32-pwm";
				status = "disabled";
				st,prescaler = < 0x2710 >;
				label = "PWM_10";
				#pwm-cells = < 0x3 >;
			};
		};
		timers11: timers@40014800 {
			compatible = "st,stm32-timers";
			reg = < 0x40014800 0x400 >;
			clocks = < &rcc 0x3 0x40000 >;
			interrupts = < 0x1a 0x0 >;
			interrupt-names = "global";
			status = "disabled";
			label = "TIMERS_11";
			pwm {
				compatible = "st,stm32-pwm";
				status = "disabled";
				st,prescaler = < 0x2710 >;
				label = "PWM_11";
				#pwm-cells = < 0x3 >;
			};
		};
		rtc: rtc@40002800 {
			compatible = "st,stm32-rtc";
			reg = < 0x40002800 0x400 >;
			interrupts = < 0x29 0x0 >;
			clocks = < &rcc 0x2 0x10000000 >;
			prescaler = < 0x8000 >;
			status = "okay";
			label = "RTC_0";
		};
		adc1: adc@40012000 {
			compatible = "st,stm32-adc";
			reg = < 0x40012000 0x400 >;
			clocks = < &rcc 0x3 0x100 >;
			interrupts = < 0x12 0x0 >;
			status = "disabled";
			label = "ADC_1";
			#io-channel-cells = < 0x1 >;
		};
		dma1: dma@40026000 {
			compatible = "st,stm32-dma-v1";
			#dma-cells = < 0x4 >;
			reg = < 0x40026000 0x400 >;
			interrupts = < 0xb 0x0 0xc 0x0 0xd 0x0 0xe 0x0 0xf 0x0 0x10 0x0 0x11 0x0 0x2f 0x0 >;
			clocks = < &rcc 0x0 0x200000 >;
			status = "disabled";
			label = "DMA_1";
			phandle = < 0xc >;
		};
		dma2: dma@40026400 {
			compatible = "st,stm32-dma-v1";
			#dma-cells = < 0x4 >;
			reg = < 0x40026400 0x400 >;
			interrupts = < 0x38 0x0 0x39 0x0 0x3a 0x0 0x3b 0x0 0x3c 0x0 0x44 0x0 0x45 0x0 0x46 0x0 >;
			clocks = < &rcc 0x0 0x400000 >;
			st,mem2mem;
			status = "disabled";
			label = "DMA_2";
		};
		spi2: spi@40003800 {
			compatible = "st,stm32-spi";
			#address-cells = < 0x1 >;
			#size-cells = < 0x0 >;
			reg = < 0x40003800 0x400 >;
			clocks = < &rcc 0x2 0x4000 >;
			interrupts = < 0x24 0x5 >;
			status = "disabled";
			label = "SPI_2";
		};
		spi3: spi@40003c00 {
			compatible = "st,stm32-spi";
			#address-cells = < 0x1 >;
			#size-cells = < 0x0 >;
			reg = < 0x40003c00 0x400 >;
			clocks = < &rcc 0x2 0x8000 >;
			interrupts = < 0x33 0x5 >;
			status = "disabled";
			label = "SPI_3";
		};
		spi4: spi@40013400 {
			compatible = "st,stm32-spi";
			#address-cells = < 0x1 >;
			#size-cells = < 0x0 >;
			reg = < 0x40013400 0x400 >;
			clocks = < &rcc 0x3 0x2000 >;
			interrupts = < 0x54 0x5 >;
			status = "disabled";
			label = "SPI_4";
		};
		i2s2: i2s@40003800 {
			compatible = "st,stm32-i2s";
			#address-cells = < 0x1 >;
			#size-cells = < 0x0 >;
			reg = < 0x40003800 0x400 >;
			clocks = < &rcc 0x2 0x4000 >;
			interrupts = < 0x24 0x5 >;
			dmas = < &dma1 0x4 0x0 0x400 0x3 &dma1 0x3 0x0 0x400 0x3 >;
			dma-names = "tx", "rx";
			status = "disabled";
			label = "I2S_2";
		};
		i2s3: i2s@40003c00 {
			compatible = "st,stm32-i2s";
			#address-cells = < 0x1 >;
			#size-cells = < 0x0 >;
			reg = < 0x40003c00 0x400 >;
			clocks = < &rcc 0x2 0x8000 >;
			interrupts = < 0x33 0x5 >;
			dmas = < &dma1 0x5 0x0 0x400 0x3 &dma1 0x0 0x0 0x400 0x3 >;
			dma-names = "tx", "rx";
			status = "disabled";
			label = "I2S_3";
		};
		usart3: serial@40004800 {
			compatible = "st,stm32-usart", "st,stm32-uart";
			reg = < 0x40004800 0x400 >;
			clocks = < &rcc 0x2 0x40000 >;
			interrupts = < 0x27 0x0 >;
			status = "okay";
			label = "UART_3";
			pinctrl-0 = < &usart3_tx_pb10 &usart3_rx_pb11 >;
			current-speed = < 0x1c200 >;
		};
		uart4: serial@40004c00 {
			compatible = "st,stm32-uart";
			reg = < 0x40004c00 0x400 >;
			clocks = < &rcc 0x2 0x80000 >;
			interrupts = < 0x34 0x0 >;
			status = "disabled";
			label = "UART_4";
		};
		uart5: serial@40005000 {
			compatible = "st,stm32-uart";
			reg = < 0x40005000 0x400 >;
			clocks = < &rcc 0x2 0x100000 >;
			interrupts = < 0x35 0x0 >;
			status = "disabled";
			label = "UART_5";
		};
		timers6: timers@40001000 {
			compatible = "st,stm32-timers";
			reg = < 0x40001000 0x400 >;
			clocks = < &rcc 0x2 0x10 >;
			interrupts = < 0x36 0x0 >;
			interrupt-names = "global";
			status = "disabled";
			label = "TIMERS_6";
			pwm {
				compatible = "st,stm32-pwm";
				status = "disabled";
				st,prescaler = < 0x2710 >;
				label = "PWM_6";
				#pwm-cells = < 0x3 >;
			};
		};
		timers7: timers@40001400 {
			compatible = "st,stm32-timers";
			reg = < 0x40001400 0x400 >;
			clocks = < &rcc 0x2 0x20 >;
			interrupts = < 0x37 0x0 >;
			interrupt-names = "global";
			status = "disabled";
			label = "TIMERS_7";
			pwm {
				compatible = "st,stm32-pwm";
				status = "disabled";
				st,prescaler = < 0x2710 >;
				label = "PWM_7";
				#pwm-cells = < 0x3 >;
			};
		};
		timers8: timers@40010400 {
			compatible = "st,stm32-timers";
			reg = < 0x40010400 0x400 >;
			clocks = < &rcc 0x3 0x2 >;
			interrupts = < 0x2b 0x0 >, < 0x2c 0x0 >, < 0x2d 0x0 >, < 0x2e 0x0 >;
			interrupt-names = "brk", "up", "trgcom", "cc";
			status = "disabled";
			label = "TIMERS_8";
			pwm {
				compatible = "st,stm32-pwm";
				status = "disabled";
				st,prescaler = < 0x2710 >;
				label = "PWM_8";
				#pwm-cells = < 0x3 >;
			};
		};
		timers12: timers@40001800 {
			compatible = "st,stm32-timers";
			reg = < 0x40001800 0x400 >;
			clocks = < &rcc 0x2 0x40 >;
			interrupts = < 0x2b 0x0 >;
			interrupt-names = "global";
			status = "disabled";
			label = "TIMERS_12";
			pwm {
				compatible = "st,stm32-pwm";
				status = "disabled";
				st,prescaler = < 0x2710 >;
				label = "PWM_12";
				#pwm-cells = < 0x3 >;
			};
		};
		timers13: timers@40001c00 {
			compatible = "st,stm32-timers";
			reg = < 0x40001c00 0x400 >;
			clocks = < &rcc 0x2 0x80 >;
			interrupts = < 0x2c 0x0 >;
			interrupt-names = "global";
			status = "disabled";
			label = "TIMERS_13";
			pwm {
				compatible = "st,stm32-pwm";
				status = "disabled";
				st,prescaler = < 0x2710 >;
				label = "PWM_13";
				#pwm-cells = < 0x3 >;
			};
		};
		timers14: timers@40002000 {
			compatible = "st,stm32-timers";
			reg = < 0x40002000 0x400 >;
			clocks = < &rcc 0x2 0x100 >;
			interrupts = < 0x2d 0x0 >;
			interrupt-names = "global";
			status = "disabled";
			label = "TIMERS_14";
			pwm {
				compatible = "st,stm32-pwm";
				status = "disabled";
				st,prescaler = < 0x2710 >;
				label = "PWM_14";
				#pwm-cells = < 0x3 >;
			};
		};
		usbotg_hs: usb_otg2: usb@40040000 {
			compatible = "st,stm32-otghs";
			reg = < 0x40040000 0x40000 >;
			interrupts = < 0x4d 0x0 >, < 0x4a 0x0 >, < 0x4b 0x0 >;
			interrupt-names = "otghs", "ep1_out", "ep1_in";
			num-bidir-endpoints = < 0x6 >;
			ram-size = < 0x1000 >;
			maximum-speed = "full-speed";
			phys = < &otghs_fs_phy >;
			clocks = < &rcc 0x0 0x20000000 >;
			status = "okay";
			label = "OTGHS";
			pinctrl-0 = < &usb_otg_hs_dm_pb14 &usb_otg_hs_dp_pb15 >;
		};
		can1: can@40006400 {
			compatible = "st,stm32-can";
			#address-cells = < 0x1 >;
			#size-cells = < 0x0 >;
			reg = < 0x40006400 0x400 >;
			interrupts = < 0x13 0x0 >, < 0x14 0x0 >, < 0x15 0x0 >, < 0x16 0x0 >;
			interrupt-names = "TX", "RX0", "RX1", "SCE";
			clocks = < &rcc 0x2 0x2000000 >;
			status = "disabled";
			label = "CAN_1";
			bus-speed = < 0x1e848 >;
			sjw = < 0x1 >;
			prop-seg = < 0x0 >;
			phase-seg1 = < 0x5 >;
			phase-seg2 = < 0x6 >;
		};
		can2: can@40006800 {
			compatible = "st,stm32-can";
			#address-cells = < 0x1 >;
			#size-cells = < 0x0 >;
			reg = < 0x40006800 0x400 >;
			interrupts = < 0x3f 0x0 >, < 0x40 0x0 >, < 0x41 0x0 >, < 0x42 0x0 >;
			interrupt-names = "TX", "RX0", "RX1", "SCE";
			clocks = < &rcc 0x2 0x6000000 >;
			master-can-reg = < 0x40006400 >;
			status = "disabled";
			label = "CAN_2";
			bus-speed = < 0x1e848 >;
			sjw = < 0x1 >;
			prop-seg = < 0x0 >;
			phase-seg1 = < 0x5 >;
			phase-seg2 = < 0x6 >;
		};
		rng: rng@50060800 {
			compatible = "st,stm32-rng";
			reg = < 0x50060800 0x400 >;
			interrupts = < 0x50 0x0 >;
			clocks = < &rcc 0x1 0x40 >;
			status = "okay";
			label = "RNG";
		};
		backup_sram: memory@40024000 {
			compatible = "st,stm32-backup-sram";
			reg = < 0x40024000 0x1000 >;
			clocks = < &rcc 0x0 0x40000 >;
			label = "BACKUP_SRAM";
			status = "disabled";
		};
		dac1: dac@40007400 {
			compatible = "st,stm32-dac";
			reg = < 0x40007400 0x400 >;
			clocks = < &rcc 0x2 0x20000000 >;
			status = "disabled";
			label = "DAC_1";
			#io-channel-cells = < 0x1 >;
		};
		mac: ethernet@40028000 {
			compatible = "st,stm32-ethernet";
			reg = < 0x40028000 0x8000 >;
			label = "ETH_0";
			interrupts = < 0x3d 0x0 >;
			clock-names = "stmmaceth", "mac-clk-tx", "mac-clk-rx", "mac-clk-ptp";
			clocks = < &rcc 0x0 0x2000000 >, < &rcc 0x0 0x4000000 >, < &rcc 0x0 0x8000000 >, < &rcc 0x0 0x10000000 >;
			status = "okay";
			pinctrl-0 = < &eth_mdc_pc1 &eth_rxd0_pc4 &eth_rxd1_pc5 &eth_ref_clk_pa1 &eth_mdio_pa2 &eth_col_pa3 &eth_crs_dv_pa7 &eth_tx_en_pg11 &eth_txd0_pg13 &eth_txd1_pg14 >;
		};
	};
	cpus {
		#address-cells = < 0x1 >;
		#size-cells = < 0x0 >;
		cpu@0 {
			device_type = "cpu";
			compatible = "arm,cortex-m4f";
			reg = < 0x0 >;
		};
	};
	sram0: memory@20000000 {
		compatible = "mmio-sram";
		reg = < 0x20000000 0x20000 >;
	};
	clocks {
		clk_hse: clk-hse {
			#clock-cells = < 0x0 >;
			compatible = "st,stm32-hse-clock";
			status = "okay";
			clock-frequency = < 0xb71b00 >;
			phandle = < 0x1c >;
		};
		clk_hsi: clk-hsi {
			#clock-cells = < 0x0 >;
			compatible = "fixed-clock";
			clock-frequency = < 0xf42400 >;
			status = "disabled";
		};
		clk_lse: clk-lse {
			#clock-cells = < 0x0 >;
			compatible = "fixed-clock";
			clock-frequency = < 0x8000 >;
			status = "disabled";
		};
		clk_lsi: clk-lsi {
			#clock-cells = < 0x0 >;
			compatible = "fixed-clock";
			clock-frequency = < 0x7d00 >;
			status = "disabled";
		};
		pll: pll {
			#clock-cells = < 0x0 >;
			compatible = "st,stm32f4-pll-clock";
			status = "okay";
			div-m = < 0x6 >;
			mul-n = < 0xa8 >;
			div-p = < 0x2 >;
			div-q = < 0x7 >;
			clocks = < &clk_hse >;
			phandle = < 0x2 >;
		};
	};
	otgfs_phy: otgfs_phy {
		compatible = "usb-nop-xceiv";
		#phy-cells = < 0x0 >;
		label = "OTGFS_PHY";
		phandle = < 0x9 >;
	};
	otghs_fs_phy: otghs_fs_phy {
		compatible = "usb-nop-xceiv";
		#phy-cells = < 0x0 >;
		label = "OTGHS_FS_PHY";
		phandle = < 0xf >;
	};
	ccm0: memory@10000000 {
		compatible = "st,stm32-ccm";
		reg = < 0x10000000 0x10000 >;
	};
	leds {
		compatible = "gpio-leds";
		green_led_1: led_1 {
			gpios = < &gpioc 0xd 0x0 >;
			label = "LED1";
		};
	};
	gpio_keys {
		compatible = "gpio-keys";
		user_button: button {
			label = "Key";
			gpios = < &gpioa 0x0 0x1 >;
		};
	};
};
